# wiz16b8m4ct3_0_WIZ16B8M4CT3 register map
Vendor: Texas Instruments
Peripheral module from a debugger description file (folder J7_AHP).
Registers are 32-bit, read-write, reset 0x0 unless marked. A register's access mark holds for its fields unless they carry their own. Offsets are as the file gives them; lines under a group give offsets from that group; [hi:lo] are bit positions; {n}, {i} and the like mark numbered series; 'fields as' and 'values as' point back to an identical list; <NAME> marks a mode.

## wiz16b8m4ct3_0_WIZ16B8M4CT3 (part 1 of 12)
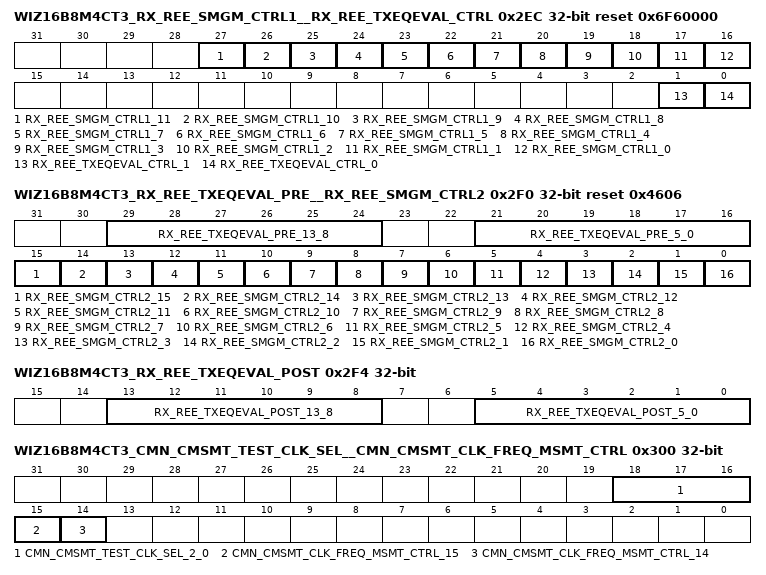
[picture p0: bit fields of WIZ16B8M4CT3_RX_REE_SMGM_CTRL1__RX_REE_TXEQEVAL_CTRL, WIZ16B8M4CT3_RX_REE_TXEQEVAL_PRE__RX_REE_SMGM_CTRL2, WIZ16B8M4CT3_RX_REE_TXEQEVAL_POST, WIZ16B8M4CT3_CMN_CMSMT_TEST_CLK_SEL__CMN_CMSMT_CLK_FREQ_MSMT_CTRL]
0x2EC WIZ16B8M4CT3_RX_REE_SMGM_CTRL1__RX_REE_TXEQEVAL_CTRL reset 0x6F60000
  [27] RX_REE_SMGM_CTRL1_11 — REE Periodic general control state machine enable standard mode 3: This bit will control if the REE periodic general control state machine will run, when xcvr_standard_mode is set to 2'b11. 1'b0 : Disabled 1'b1 : Enabled
  [26] RX_REE_SMGM_CTRL1_10 — REE Periodic general control state machine enable standard mode 2: This bit will control if the REE periodic general control state machine will run, when xcvr_standard_mode is set to 2'b10. 1'b0 : Disabled 1'b1 : Enabled
  [25] RX_REE_SMGM_CTRL1_9 — REE Periodic general control state machine enable standard mode 1: This bit will control if the REE periodic general control state machine will run, when xcvr_standard_mode is set to 2'b01. 1'b0 : Disabled 1'b1 : Enabled
  [24] RX_REE_SMGM_CTRL1_8 — REE Periodic general control state machine enable standard mode 0: This bit will control if the REE periodic general control state machine will run, when xcvr_standard_mode is set to 2'b00. 1'b0 : Disabled 1'b1 : Enabled
  [23] RX_REE_SMGM_CTRL1_7 — REE general control state machine 2 enable standard mode 3: This bit will control if the REE general control state machine 2 will run, when xcvr_standard_mode is set to 2'b11. 1'b0 : Disabled 1'b1 : Enabled
  [22] RX_REE_SMGM_CTRL1_6 — REE general control state machine 2 enable standard mode 2: This bit will control if the REE general control state machine 2 will run, when xcvr_standard_mode is set to 2'b10. 1'b0 : Disabled 1'b1 : Enabled
  [21] RX_REE_SMGM_CTRL1_5 — REE general control state machine 2 enable standard mode 1: This bit will control if the REE general control state machine 2 will run, when xcvr_standard_mode is set to 2'b01. 1'b0 : Disabled 1'b1 : Enabled
  [20] RX_REE_SMGM_CTRL1_4 — REE general control state machine 2 enable standard mode 0: This bit will control if the REE general control state machine 2 will run, when xcvr_standard_mode is set to 2'b00. 1'b0 : Disabled 1'b1 : Enabled
  [19] RX_REE_SMGM_CTRL1_3 — REE general control state machine 1 enable standard mode 3: This bit will control if the REE general control state machine 1 will run, when xcvr_standard_mode is set to 2'b11. 1'b0 : Disabled 1'b1 : Enabled
  [18] RX_REE_SMGM_CTRL1_2 — REE general control state machine 1 enable standard mode 2: This bit will control if the REE general control state machine 1 will run, when xcvr_standard_mode is set to 2'b10. 1'b0 : Disabled 1'b1 : Enabled
  [17] RX_REE_SMGM_CTRL1_1 — REE general control state machine 1 enable standard mode 1: This bit will control if the REE general control state machine 1 will run, when xcvr_standard_mode is set to 2'b01. 1'b0 : Disabled 1'b1 : Enabled
  [16] RX_REE_SMGM_CTRL1_0 — REE general control state machine 1 enable standard mode 0: This bit will control if the REE general control state machine 1 will run, when xcvr_standard_mode is set to 2'b00. 1'b0 : Disabled 1'b1 : Enabled
  [1] RX_REE_TXEQEVAL_CTRL_1 — TX equalization evaluation counter reset on gen mode change: Controls if the incremental evaluation counter will be reset to its starting value when changing gen modes. When enabled, the reset will take place on the first equalization evaluation after a gen mode change has taken place. 1'b0 : Gen mode change reset disabled. 1'b1 : Gen mode change reset enabled.
  [0] RX_REE_TXEQEVAL_CTRL_0 — TX main coefficient direction change control: This bit controls the function of the main coefficient direction change. 1'b0 : The main coefficient will always return a value of no change (2'b00), no matter what the pre and post cursor coefficient direction changes are. 1'b1 : The main coefficient will generate a return value as a function of the pre and post cursor coefficient direction change. If an increment request exists on the pre or post cursor coefficient direction change, a decrement request will be returned for the main coefficient. Similarly, if a decrement request exists on the pre or post cursor coefficient direction change, an increment request will be returned for the main coefficient.
0x2F0 WIZ16B8M4CT3_RX_REE_TXEQEVAL_PRE__RX_REE_SMGM_CTRL2 access per field reset 0x4606
  [29:24] RX_REE_TXEQEVAL_PRE_13_8 ro — TX equalization evaluator pre-emphasis increment count: Contains a count of the total number of pre-emphasis increment responses that have taken place during the TX equalization evaluator process.
  [21:16] RX_REE_TXEQEVAL_PRE_5_0 ro — TX equalization evaluator pre-emphasis decrement count: Contains a count of the total number of pre-emphasis decrement responses that have taken place during the TX equalization evaluator process.
  [15] RX_REE_SMGM_CTRL2_15 rw — REE PCIe Gen 3 TX equalization state machine E path en standard mode 3: This bit controls if the REE PCIE Gen 3 TX equalization state machine will enable the analog E path when xcvr_standard_mode is set to 2'b11. 1'b0 : Disabled 1'b1 : Enabled
  [14] RX_REE_SMGM_CTRL2_14 rw — REE PCIe Gen 3 TX equalization state machine E path en standard mode 2: This bit controls if the REE PCIE Gen 3 TX equalization state machine will enable the analog E path when xcvr_standard_mode is set to 2'b10. 1'b0 : Disabled 1'b1 : Enabled
  [13] RX_REE_SMGM_CTRL2_13 rw — REE PCIe Gen 3 TX equalization state machine E path en standard mode 1: This bit controls if the REE PCIE Gen 3 TX equalization state machine will enable the analog E path when xcvr_standard_mode is set to 2'b01. 1'b0 : Disabled 1'b1 : Enabled
  [12] RX_REE_SMGM_CTRL2_12 rw — REE PCIe Gen 3 TX equalization state machine E path en standard mode 0: This bit controls if the REE PCIE Gen 3 TX equalization state machine will enable the analog E path when xcvr_standard_mode is set to 2'b00. 1'b0 : Disabled 1'b1 : Enabled
  [11] RX_REE_SMGM_CTRL2_11 rw — REE Periodic general control state machine E path en standard mode 3: This bit controls if the REE periodic general control state machine will enable the analog E path when xcvr_standard_mode is set to 2'b11. 1'b0 : Disabled 1'b1 : Enabled
  [10] RX_REE_SMGM_CTRL2_10 rw — REE Periodic general control state machine E path en standard mode 2: This bit controls if the REE periodic general control state machine will enable the analog E path when xcvr_standard_mode is set to 2'b10. 1'b0 : Disabled 1'b1 : Enabled
  [9] RX_REE_SMGM_CTRL2_9 rw — REE Periodic general control state machine E path en standard mode 1: This bit controls if the REE periodic general control state machine will enable the analog E path when xcvr_standard_mode is set to 2'b01. 1'b0 : Disabled 1'b1 : Enabled
  [8] RX_REE_SMGM_CTRL2_8 rw — REE Periodic general control state machine E path en standard mode 0: This bit controls if the REE periodic general control state machine will enable the analog E path when xcvr_standard_mode is set to 2'b00. 1'b0 : Disabled 1'b1 : Enabled
  [7] RX_REE_SMGM_CTRL2_7 rw — REE general control state machine 2 E path en standard mode 3: This bit controls if the REE general control state machine 2 will enable the analog E path when xcvr_standard_mode is set to 2'b11. 1'b0 : Disabled 1'b1 : Enabled
  [6] RX_REE_SMGM_CTRL2_6 rw — REE general control state machine 2 E path en standard mode 2: This bit controls if the REE general control state machine 2 will enable the analog E path when xcvr_standard_mode is set to 2'b10. 1'b0 : Disabled 1'b1 : Enabled
  [5] RX_REE_SMGM_CTRL2_5 rw — REE general control state machine 2 E path en standard mode 1: This bit controls if the REE general control state machine 2 will enable the analog E path when xcvr_standard_mode is set to 2'b01. 1'b0 : Disabled 1'b1 : Enabled
  [4] RX_REE_SMGM_CTRL2_4 rw — REE general control state machine 2 E path en standard mode 0: This bit controls if the REE general control state machine 2 will enable the analog E path when xcvr_standard_mode is set to 2'b00. 1'b0 : Disabled 1'b1 : Enabled
  [3] RX_REE_SMGM_CTRL2_3 rw — REE general control state machine 1 E path en standard mode 3: This bit controls if the REE general control state machine 1 will enable the analog E path when xcvr_standard_mode is set to 2'b11. 1'b0 : Disabled 1'b1 : Enabled
  [2] RX_REE_SMGM_CTRL2_2 rw — REE general control state machine 1 E path en standard mode 2: This bit controls if the REE general control state machine 1 will enable the analog E path when xcvr_standard_mode is set to 2'b10. 1'b0 : Disabled 1'b1 : Enabled
  [1] RX_REE_SMGM_CTRL2_1 rw — REE general control state machine 1 E path en standard mode 1: This bit controls if the REE general control state machine 1 will enable the analog E path when xcvr_standard_mode is set to 2'b01. 1'b0 : Disabled 1'b1 : Enabled
  [0] RX_REE_SMGM_CTRL2_0 rw — REE general control state machine 1 E path en standard mode 0: This bit controls if the REE general control state machine 1 will enable the analog E path when xcvr_standard_mode is set to 2'b00. 1'b0 : Disabled 1'b1 : Enabled
0x2F4 WIZ16B8M4CT3_RX_REE_TXEQEVAL_POST ro
  [13:8] RX_REE_TXEQEVAL_POST_13_8 — TX equalization evaluator post-emphasis increment count: Contains a count of the total number of post-emphasis increment responses that have taken place during the TX equalization evaluator process.
  [5:0] RX_REE_TXEQEVAL_POST_5_0 — TX equalization evaluator post-emphasis decrement count: Contains a count of the total number of post-emphasis decrement responses that have taken place during the TX equalization evaluator process.
0x300 WIZ16B8M4CT3_CMN_CMSMT_TEST_CLK_SEL__CMN_CMSMT_CLK_FREQ_MSMT_CTRL access per field
  [18:16] CMN_CMSMT_TEST_CLK_SEL_2_0 rw — Test clock select: This field drives the test_clk_select pin, in order to control an external MUX for selecting between multiple test clocks to measure. The following is the encoding for this field, and the clock each value selects. 3'b000 : PLL 0 reference clock 3'b001 : PLL 0 feedback divider clock 3'b010 : PLL 0 full rate clock 3'b011 : PLL 1 reference clock 3'b100 : PLL 1 feedback divider clock 3'b101 : PLL 1 full rate clock 3'b110 : Process monitor clock 3'b111 : Signal detect clock
  [15] CMN_CMSMT_CLK_FREQ_MSMT_CTRL_15 rw — Run test clock measurement: Activating (1'b1) this bit will run the test clock measurement process. This bit must remain active until the test clock measurement process is complete, as indicated by the test clock measurement done bit in this register. To start another measurement process, this bit must first be driven inactive then driven active again. Note: Both of the clocks used to generate the ref_clk and test_clk clocks must be active prior to setting or clearing this bit. Note: The values in the Test clock selection register and Reference clock timer value register must be set prior to activating this bit.
  [14] CMN_CMSMT_CLK_FREQ_MSMT_CTRL_14 ro — Test clock measurement done: This bit will be set to 1'b1 when the test clock measurement process is complete. It will be cleared by the deactivation of the start test clock measurement bit in this register.
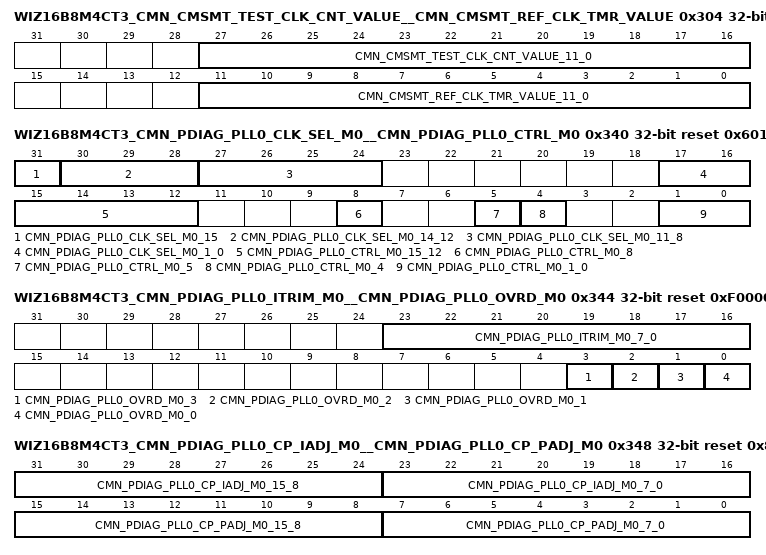
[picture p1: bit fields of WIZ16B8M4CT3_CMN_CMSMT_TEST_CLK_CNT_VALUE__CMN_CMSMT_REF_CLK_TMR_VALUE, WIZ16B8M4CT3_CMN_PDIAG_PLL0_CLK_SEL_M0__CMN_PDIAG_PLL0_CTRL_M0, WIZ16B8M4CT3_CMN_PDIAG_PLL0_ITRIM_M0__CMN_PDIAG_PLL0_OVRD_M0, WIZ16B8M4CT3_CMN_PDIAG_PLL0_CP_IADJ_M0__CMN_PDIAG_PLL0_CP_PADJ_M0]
0x304 WIZ16B8M4CT3_CMN_CMSMT_TEST_CLK_CNT_VALUE__CMN_CMSMT_REF_CLK_TMR_VALUE access per field
  [27:16] CMN_CMSMT_TEST_CLK_CNT_VALUE_11_0 ro — Test clock counter value: When the test clock measurement process is complete, the value in this field specifies the number of test clock cycles that were counted in the time specified by the reference clock timer value. This field is only valid while the test clock measurement done bit in the Clock frequency measurement control register is active.
  [11:0] CMN_CMSMT_REF_CLK_TMR_VALUE_11_0 rw — Reference clock timer value : This specifies the amount of time, in reference clock cycles, to count test clock cycles. This value minus 1 is loaded into the reference clock timer. A value of 0 for this field is not valid when running this function.
0x340 WIZ16B8M4CT3_CMN_PDIAG_PLL0_CLK_SEL_M0__CMN_PDIAG_PLL0_CTRL_M0 reset 0x6011012
  [31] CMN_PDIAG_PLL0_CLK_SEL_M0_15 — PLL 0 clock 1 divider enable: This bit enables the divider used to generate the cmnda_pll0_clk_1, from the PLL high speed clock.
  [30:28] CMN_PDIAG_PLL0_CLK_SEL_M0_14_12 — PLL 0 clock 1 divider select: This field selects the divider value used to generate the cmnda_pll0_clk_1, from the PLL high speed clock, by driving the cmnda_pll0_clk_1_div_sel signal to the analog. The encoding of this signal is as follows. All codes currently result in divide by 16.
  [27:24] CMN_PDIAG_PLL0_CLK_SEL_M0_11_8 — PLL 0 clock 0 and derived reference clock divider select: This field selects the divider value used to generate the cmnda_pll0_clk_0 and derived reference clock, from the PLL high speed clock, by driving the cmnda_pll0_clk_0_div_sel signal to the analog. The encoding of this signal is as follows. Note: There are different divider values per bit for associated with each clock.
  [17:16] CMN_PDIAG_PLL0_CLK_SEL_M0_1_0 — PLL 0 clock select: This field selects one of 3 possible high speed output clocks from PLL 0, to drive on the high speed analog clock 0, by driving the cmnda_pll0_clk_sel signal to the analog. The encoding for this is as follows. 2'b00: Divide by 1 2'b01: Divide by 2 2'b10: Divide by 4 2'b11: Reserved
  [15:12] CMN_PDIAG_PLL0_CTRL_M0_15_12 — This field controls the Ring VCO Frequency drift with temperature. It controls the mix of vtref bias and external bias to keep the temperature drift for the ring low, by driving the cmnda_pll0_vco_ring_cmos_sel signal going into the common analog.
  [8] CMN_PDIAG_PLL0_CTRL_M0_8 — PLL VCO select: Selects the VCO mode of operation, by driving the cmnda_pll0_vco_sel signal going into the common analog. 1'b0: LC tank mode 1'b1: Ring oscillator mode
  [5] CMN_PDIAG_PLL0_CTRL_M0_5 — PLL feedback divider clock select: This signal selects which internal PLL clock will be used to drive the cmnda_pll0_fb_divider_clk, by driving the cmnda_pll0_fb_divider_clk_sel signal going into the common analog. 1'b0: Feedback divider clock 1'b1: PLL digital rate clock
  [4] CMN_PDIAG_PLL0_CTRL_M0_4 — PLL feedback divider pre-scale: controls the feedback divider pre-scale, by driving the cmnda_pll0_div24_sel signal going into the common analog. One should read the description of the PLL in section 10.4 Dual VCO PLL on page 411 for detailed information about the function of this divider control. 1'b0: Divide by 2 - When using the delta sigma modulator, this setting results in lower noise on the PLL output clock, but higher power. 1'b1: Divide by 4 - When using the delta sigma modulator, this setting results in higher noise on the PLL output clock, but lower power. This setting is ideal for cases when the delta sigma modulator is not used, because is results in both lower noise and lower power.
  [1:0] CMN_PDIAG_PLL0_CTRL_M0_1_0 — PLL PFD reset delay: Controls the minimum reset pulse width for the PFD. This drives the cmnda_pll0_pfd_rst_dly signal going into the common analog. The following lists the reset pulse width values for typical conditions for each of the possible values for this field. 2'b00 : Delay = 257.5 pSec (minimum) 2'b01 : Delay = 337.4 pSec 2'b10 : Delay = 415.2 pSec 2'b11 : Delay = 493.2 pSec (maximum)
0x344 WIZ16B8M4CT3_CMN_PDIAG_PLL0_ITRIM_M0__CMN_PDIAG_PLL0_OVRD_M0 access per field reset 0xF0000
  [23:16] CMN_PDIAG_PLL0_ITRIM_M0_7_0 rw — PLL VCO bias current trim code: Controls the tank currents in the PLL LC tank circuit. This field drives the cmnda_pll0_vco_bias_current_trim signal going to the analog.
  [3] CMN_PDIAG_PLL0_OVRD_M0_3 rw — PLL VCO calibration enable override enable: When active (1'b1), the PLL VCO calibration enable override bit in this register, can be used to directly control the enable of the VCO calibration function in the PLL (instead of the VCO calibration module).
  [2] CMN_PDIAG_PLL0_OVRD_M0_2 rw — PLL VCO calibration enable override: When enabled by the PLL VCO calibration enable override enable bit in this register, this bit will directly control the enable of the VCO calibration function in the PLL.
  [1] CMN_PDIAG_PLL0_OVRD_M0_1 rw — PLL phase lock detect enable : Enables the diagnostic PLL phase lock detect function in the analog. This activates the cmnda_pll0_ph_lock_en signal going into the analog.
  [0] CMN_PDIAG_PLL0_OVRD_M0_0 ro — PLL phase lock detected : When enabled by the PLL phase lock detect enable bit in this register, this bit indicates that a PLL phase lock has been detected. This is the current value of the cmnda_pll0_ph_lock_detect signal coming from the analog.
0x348 WIZ16B8M4CT3_CMN_PDIAG_PLL0_CP_IADJ_M0__CMN_PDIAG_PLL0_CP_PADJ_M0 reset 0x8080028
  [31:24] CMN_PDIAG_PLL0_CP_IADJ_M0_15_8 — PLL charge pump integral path capacitance adjust: Adjusts the charge pump integral path capacitance, by driving the cmnda_pll0_cp_int_cap_adj signal going to the analog.
  [23:16] CMN_PDIAG_PLL0_CP_IADJ_M0_7_0 — PLL charge pump integral path current adjust: Adjusts the charge pump integral path current, by driving the cmnda_pll0_cp_int_cur_adj signal going to the analog.
  [15:8] CMN_PDIAG_PLL0_CP_PADJ_M0_15_8 — PLL charge pump proportional path capacitance adjust: Adjusts the charge pump proportional path capacitance, by driving the cmnda_pll0_cp_prop_cap_adj signal going to the analog.
  [7:0] CMN_PDIAG_PLL0_CP_PADJ_M0_7_0 — PLL charge pump proportional path current adjust: Adjusts the charge pump proportional path current, by driving the cmnda_pll0_cp_prop_cur_adj signal going to the analog.
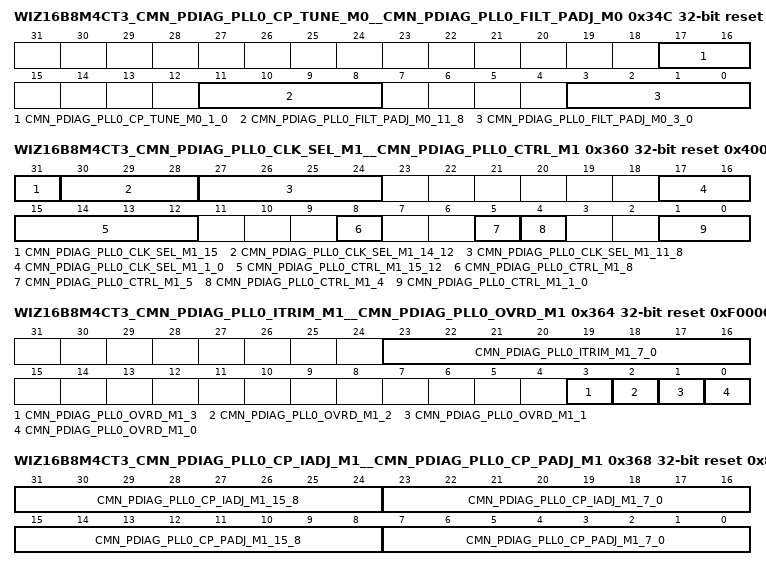
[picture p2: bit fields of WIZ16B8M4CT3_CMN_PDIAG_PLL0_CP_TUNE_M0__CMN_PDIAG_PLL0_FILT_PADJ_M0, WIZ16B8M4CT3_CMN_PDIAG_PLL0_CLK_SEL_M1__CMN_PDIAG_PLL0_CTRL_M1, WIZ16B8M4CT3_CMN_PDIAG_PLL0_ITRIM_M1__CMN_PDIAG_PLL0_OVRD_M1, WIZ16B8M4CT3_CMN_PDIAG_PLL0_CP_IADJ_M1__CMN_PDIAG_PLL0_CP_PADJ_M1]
0x34C WIZ16B8M4CT3_CMN_PDIAG_PLL0_CP_TUNE_M0__CMN_PDIAG_PLL0_FILT_PADJ_M0 reset 0x10000
  [17:16] CMN_PDIAG_PLL0_CP_TUNE_M0_1_0 — PLL charge pump calibration reference voltage tune: Adjusts the charge pump calibration reference voltage, by driving the cmnda_pll0_cp_vref_tune signal going to the analog. 2'b00 : minimum 2'b01 2'b10 2'b11 maximum
  [11:8] CMN_PDIAG_PLL0_FILT_PADJ_M0_11_8 — PLL proportional path filter capacitance adjust: Adjusts the proportional path filter capacitance, by driving the cmnda_pll0_filt_c_adj signal going to the analog.
  [3:0] CMN_PDIAG_PLL0_FILT_PADJ_M0_3_0 — PLL proportional path filter resistance adjust: Adjusts the proportional path filter resistance, by driving the cmnda_pll0_filt_r_adj signal going to the analog.
0x360 WIZ16B8M4CT3_CMN_PDIAG_PLL0_CLK_SEL_M1__CMN_PDIAG_PLL0_CTRL_M1 reset 0x4001012
  [31] CMN_PDIAG_PLL0_CLK_SEL_M1_15 — PLL 0 clock 1 divider enable: This bit enables the divider used to generate the cmnda_pll0_clk_1, from the PLL high speed clock.
  [30:28] CMN_PDIAG_PLL0_CLK_SEL_M1_14_12 — PLL 0 clock 1 divider select: This field selects the divider value used to generate the cmnda_pll0_clk_1, from the PLL high speed clock, by driving the cmnda_pll0_clk_1_div_sel signal to the analog. The encoding of this signal is as follows. All codes currently result in divide by 16.
  [27:24] CMN_PDIAG_PLL0_CLK_SEL_M1_11_8 — PLL 0 clock 0 and derived reference clock divider select: This field selects the divider value used to generate the cmnda_pll0_clk_0 and derived reference clock, from the PLL high speed clock, by driving the cmnda_pll0_clk_0_div_sel signal to the analog. The encoding of this signal is as follows. Note: There are different divider values per bit for associated with each clock.
  [17:16] CMN_PDIAG_PLL0_CLK_SEL_M1_1_0 — PLL 0 clock select: This field selects one of 3 possible high speed output clocks from PLL 0, to drive on the high speed analog clock 0, by driving the cmnda_pll0_clk_sel signal to the analog. The encoding for this is as follows. 2'b00: Divide by 1 2'b01: Divide by 2 2'b10: Divide by 4 2'b11: Reserved
  [15:12] CMN_PDIAG_PLL0_CTRL_M1_15_12 — This field controls the Ring VCO Frequency drift with temperature. It controls the mix of vtref bias and external bias to keep the temperature drift for the ring low, by driving the cmnda_pll0_vco_ring_cmos_sel signal going into the common analog.
  [8] CMN_PDIAG_PLL0_CTRL_M1_8 — PLL VCO select: Selects the VCO mode of operation, by driving the cmnda_pll0_vco_sel signal going into the common analog. 1'b0: LC tank mode 1'b1: Ring oscillator mode
  [5] CMN_PDIAG_PLL0_CTRL_M1_5 — PLL feedback divider clock select: This signal selects which internal PLL clock will be used to drive the cmnda_pll0_fb_divider_clk,driving the cmnda_pll0_fb_divider_clk_sel signal going into the common analog. 1'b0: Feedback divider clock 1'b1: PLL digital rate clock
  [4] CMN_PDIAG_PLL0_CTRL_M1_4 — PLL feedback divider pre-scale: controls the feedback divider pre-scale, by driving the cmnda_pll0_div24_sel signal going into the common analog. One should read the description of the PLL in section 10.4 Dual VCO PLL on page 411 for detailed information about the function of this divider control. 1'b0: Divide by 2 - When using the delta sigma modulator, this setting results in lower noise on the PLL output clock, but higher power. 1'b1: Divide by 4 - When using the delta sigma modulator, this setting results in higher noise on the PLL output clock, but lower power. This setting is ideal for cases when the delta sigma modulator is not used, because is results in both lower noise and lower power.
  [1:0] CMN_PDIAG_PLL0_CTRL_M1_1_0 — PLL PFD reset delay: Controls the minimum reset pulse width for the PFD. This drives the cmnda_pll0_pfd_rst_dly signal going into the common analog. The following lists the reset pulse width values for typical conditions for each of the possible values for this field. 2'b00 : Delay = 257.5 pSec (minimum) 2'b01 : Delay = 337.4 pSec 2'b10 : Delay = 415.2 pSec 2'b11 : Delay = 493.2 pSec (maximum)
0x364 WIZ16B8M4CT3_CMN_PDIAG_PLL0_ITRIM_M1__CMN_PDIAG_PLL0_OVRD_M1 access per field reset 0xF0000
  [23:16] CMN_PDIAG_PLL0_ITRIM_M1_7_0 rw — PLL VCO bias current trim code: Controls the tank currents in the PLL LC tank circuit. This field drives the cmnda_pll0_vco_bias_current_trim signal going to the analog.
  [3] CMN_PDIAG_PLL0_OVRD_M1_3 rw — PLL VCO calibration enable override enable: When active (1'b1), the PLL VCO calibration enable override bit in this register, can be used to directly control the enable of the VCO calibration function in the PLL (instead of the VCO calibration module).
  [2] CMN_PDIAG_PLL0_OVRD_M1_2 rw — PLL VCO calibration enable override: When enabled by the PLL VCO calibration enable override enable bit in this register, this bit will directly control the enable of the VCO calibration function in the PLL.
  [1] CMN_PDIAG_PLL0_OVRD_M1_1 rw — PLL phase lock detect enable : Enables the diagnostic PLL phase lock detect function in the analog. This activates the cmnda_pll0_ph_lock_en signal going into the analog.
  [0] CMN_PDIAG_PLL0_OVRD_M1_0 ro — PLL phase lock detected : When enabled by the PLL phase lock detect enable bit in this register, this bit indicates that a PLL phase lock has been detected. This is the current value of the cmnda_pll0_ph_lock_detect signal coming from the analog.
0x368 WIZ16B8M4CT3_CMN_PDIAG_PLL0_CP_IADJ_M1__CMN_PDIAG_PLL0_CP_PADJ_M1 reset 0x8080128
  [31:24] CMN_PDIAG_PLL0_CP_IADJ_M1_15_8 — PLL charge pump integral path capacitance adjust: Adjusts the charge pump integral path capacitance, by driving the cmnda_pll0_cp_int_cap_adj signal going to the analog.
  [23:16] CMN_PDIAG_PLL0_CP_IADJ_M1_7_0 — PLL charge pump integral path current adjust: Adjusts the charge pump integral path current, by driving the cmnda_pll0_cp_int_cur_adj signal going to the analog.
  [15:8] CMN_PDIAG_PLL0_CP_PADJ_M1_15_8 — PLL charge pump proportional path capacitance adjust: Adjusts the charge pump proportional path capacitance, by driving the cmnda_pll0_cp_prop_cap_adj signal going to the analog.
  [7:0] CMN_PDIAG_PLL0_CP_PADJ_M1_7_0 — PLL charge pump proportional path current adjust: Adjusts the charge pump proportional path current, by driving the cmnda_pll0_cp_prop_cur_adj signal going to the analog.
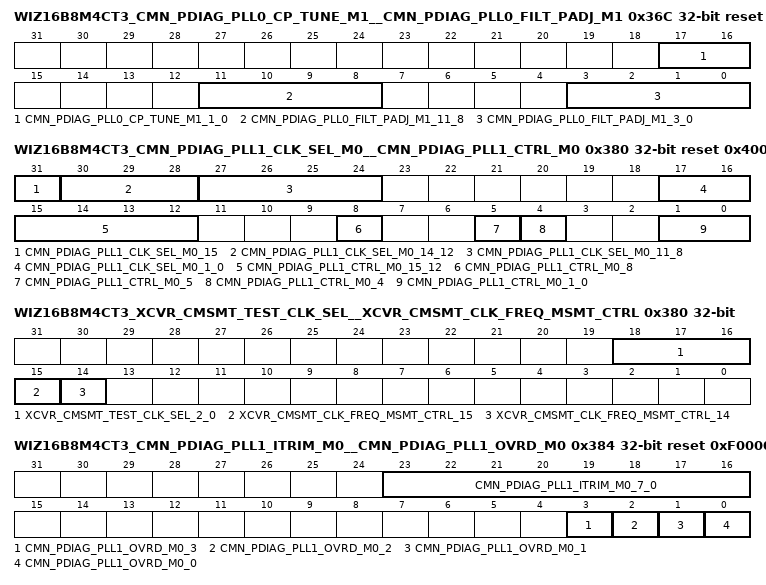
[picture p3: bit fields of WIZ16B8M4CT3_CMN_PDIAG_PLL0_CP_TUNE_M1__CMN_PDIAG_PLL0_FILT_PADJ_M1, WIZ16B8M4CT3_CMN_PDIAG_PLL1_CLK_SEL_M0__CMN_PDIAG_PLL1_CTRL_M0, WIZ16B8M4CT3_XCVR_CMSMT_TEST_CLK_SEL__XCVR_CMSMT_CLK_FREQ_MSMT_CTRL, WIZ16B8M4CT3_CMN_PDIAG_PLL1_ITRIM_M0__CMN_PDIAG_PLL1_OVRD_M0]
0x36C WIZ16B8M4CT3_CMN_PDIAG_PLL0_CP_TUNE_M1__CMN_PDIAG_PLL0_FILT_PADJ_M1 reset 0x10000
  [17:16] CMN_PDIAG_PLL0_CP_TUNE_M1_1_0 — PLL charge pump calibration reference voltage tune: Adjusts the charge pump calibration reference voltage, by driving the cmnda_pll0_cp_vref_tune signal going to the analog. 2'b00 : minimum 2'b01 2'b10 2'b11 maximum
  [11:8] CMN_PDIAG_PLL0_FILT_PADJ_M1_11_8 — PLL proportional path filter capacitance adjust: Adjusts the proportional path filter capacitance, by driving the cmnda_pll0_filt_c_adj signal going to the analog.
  [3:0] CMN_PDIAG_PLL0_FILT_PADJ_M1_3_0 — PLL proportional path filter resistance adjust: Adjusts the proportional path filter resistance, by driving the cmnda_pll0_filt_r_adj signal going to the analog.
0x380 WIZ16B8M4CT3_CMN_PDIAG_PLL1_CLK_SEL_M0__CMN_PDIAG_PLL1_CTRL_M0 reset 0x4001012
  [31] CMN_PDIAG_PLL1_CLK_SEL_M0_15 — PLL 1 clock 1 divider enable: This bit enables the divider used to generate the cmnda_pll1_clk_1, from the PLL high speed clock.
  [30:28] CMN_PDIAG_PLL1_CLK_SEL_M0_14_12 — PLL 1 clock 1 divider select: This field selects the divider value used to generate the cmnda_pll1_clk_1, from the PLL high speed clock, by driving the cmnda_pll1_clk_1_div_sel signal to the analog. The encoding of this signal is as follows. All codes currently result in divide by 16.
  [27:24] CMN_PDIAG_PLL1_CLK_SEL_M0_11_8 — PLL 1 clock 0 and derived reference clock divider select: This field selects the divider value used to generate the cmnda_pll1_clk_0 and derived reference clock, from the PLL high speed clock, by driving the cmnda_pll1_clk_0_div_sel signal to the analog. The encoding of this signal is as follows. Note: There are different divider values per bit for associated with each clock.
  [17:16] CMN_PDIAG_PLL1_CLK_SEL_M0_1_0 — PLL 1 clock select: This field selects one of 3 possible high speed output clocks from PLL 1, to drive on the high speed analog clock 1, by driving the cmnda_pll1_clk_sel signal to the analog. The encoding for this is as follows. 2'b00: Divide by 1 2'b01: Divide by 2 2'b10: Divide by 4 2'b11: Reserved
  [15:12] CMN_PDIAG_PLL1_CTRL_M0_15_12 — This field controls the Ring VCO Frequency drift with temperature. It controls the mix of vtref bias and external bias to keep the temperature drift for the ring low, by driving the cmnda_pll1_vco_ring_cmos_sel signal going into the common analog.
  [8] CMN_PDIAG_PLL1_CTRL_M0_8 — PLL VCO select: Selects the VCO mode of operation, by driving the cmnda_pll1_vco_sel signal going into the common analog. 1'b0: LC tank mode 1'b1: Ring oscillator mode
  [5] CMN_PDIAG_PLL1_CTRL_M0_5 — PLL feedback divider clock select: This signal selects which internal PLL clock will be used to drive the cmnda_pll1_fb_divider_clk,driving the cmnda_pll1_fb_divider_clk_sel signal going into the common analog. 1'b0: Feedback divider clock 1'b1: PLL digital rate clock
  [4] CMN_PDIAG_PLL1_CTRL_M0_4 — PLL feedback divider pre-scale: controls the feedback divider pre-scale, by driving the cmnda_pll1_div24_sel signal going into the common analog. One should read the description of the PLL in section 10.4 Dual VCO PLL on page 411 for detailed information about the function of this divider control. 1'b0: Divide by 2 - When using the delta sigma modulator, this setting results in lower noise on the PLL output clock, but higher power. 1'b1: Divide by 4 - When using the delta sigma modulator, this setting results in higher noise on the PLL output clock, but lower power. This setting is ideal for cases when the delta sigma modulator is not used, because is results in both lower noise and lower power.
  [1:0] CMN_PDIAG_PLL1_CTRL_M0_1_0 — PLL PFD reset delay: Controls the minimum reset pulse width for the PFD. This drives the cmnda_pll1_pfd_rst_dly signal going into the common analog. The following lists the reset pulse width values for typical conditions for each of the possible values for this field. 2'b00 : Delay = 257.5 pSec (minimum) 2'b01 : Delay = 337.4 pSec 2'b10 : Delay = 415.2 pSec 2'b11 : Delay = 493.2 pSec (maximum)
0x380 WIZ16B8M4CT3_XCVR_CMSMT_TEST_CLK_SEL__XCVR_CMSMT_CLK_FREQ_MSMT_CTRL access per field
  [18:16] XCVR_CMSMT_TEST_CLK_SEL_2_0 rw — Test clock select: This field drives the test_clk_select pin, in order to control an external MUX for selecting between multiple test clocks to measure. The following is the encoding for this field, and the clock each value selects. 3'b000 : Transmitter data clock 3'b001 : Serializer clock 3'b010 : Receiver data clock 3'b011 : Deserializer clock 3'b100 : Receiver 2X data clock 3'b101 : Deserializer 2X clock 3'b110 : Signal detect clock 3'b111 : Reserved
  [15] XCVR_CMSMT_CLK_FREQ_MSMT_CTRL_15 rw — Run test clock measurement: Activating (1'b1) this bit will run the test clock measurement process. This bit must remain active until the test clock measurement process is complete, as indicated by the test clock measurement done bit in this register. To start another measurement process, this bit must first be driven inactive then driven active again. Note: Both of the clocks used to generate the ref_clk and test_clk clocks must be active prior to setting or clearing this bit. Note: The values in the Test clock selection register and Reference clock timer value register must be set prior to activating this bit.
  [14] XCVR_CMSMT_CLK_FREQ_MSMT_CTRL_14 ro — Test clock measurement done: This bit will be set to 1'b1 when the test clock measurement process is complete. It will be cleared by the deactivation of the start test clock measurement bit in this register.
0x384 WIZ16B8M4CT3_CMN_PDIAG_PLL1_ITRIM_M0__CMN_PDIAG_PLL1_OVRD_M0 access per field reset 0xF0000
  [23:16] CMN_PDIAG_PLL1_ITRIM_M0_7_0 rw — PLL VCO bias current trim code: Controls the tank currents in the PLL LC tank circuit. This field drives the cmnda_pll1_vco_bias_current_trim signal going to the analog.
  [3] CMN_PDIAG_PLL1_OVRD_M0_3 rw — PLL VCO calibration enable override enable: When active (1'b1), the PLL VCO calibration enable override bit in this register, can be used to directly control the enable of the VCO calibration function in the PLL (instead of the VCO calibration module).
  [2] CMN_PDIAG_PLL1_OVRD_M0_2 rw — PLL VCO calibration enable override: When enabled by the PLL VCO calibration enable override enable bit in this register, this bit will directly control the enable of the VCO calibration function in the PLL.
  [1] CMN_PDIAG_PLL1_OVRD_M0_1 rw — PLL phase lock detect enable : Enables the diagnostic PLL phase lock detect function in the analog. This activates the cmnda_pll1_ph_lock_en signal going into the analog.
  [0] CMN_PDIAG_PLL1_OVRD_M0_0 ro — PLL phase lock detected : When enabled by the PLL phase lock detect enable bit in this register, this bit indicates that a PLL phase lock has been detected. This is the current value of the cmnda_pll1_ph_lock_detect signal coming from the analog.
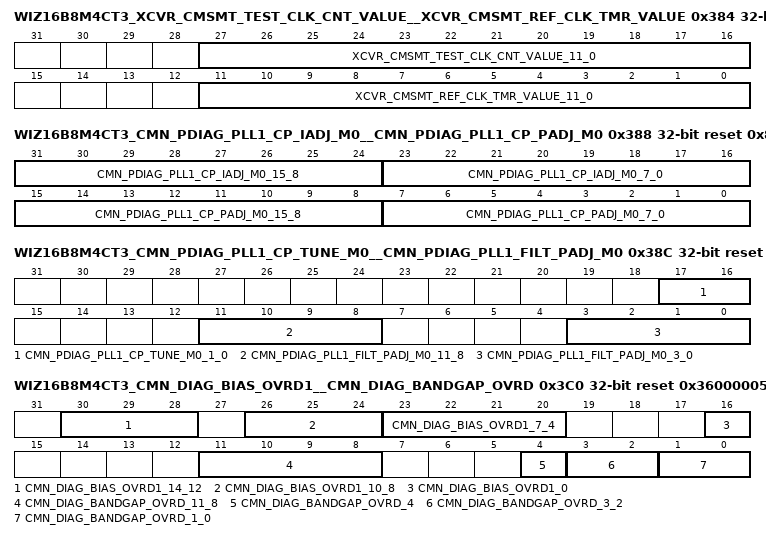
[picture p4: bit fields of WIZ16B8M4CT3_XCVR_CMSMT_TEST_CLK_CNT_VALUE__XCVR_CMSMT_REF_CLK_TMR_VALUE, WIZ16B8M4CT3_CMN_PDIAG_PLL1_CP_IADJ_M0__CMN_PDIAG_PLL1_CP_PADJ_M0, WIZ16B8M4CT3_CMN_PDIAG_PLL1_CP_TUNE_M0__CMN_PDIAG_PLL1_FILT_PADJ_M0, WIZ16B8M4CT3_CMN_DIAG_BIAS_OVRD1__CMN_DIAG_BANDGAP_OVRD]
0x384 WIZ16B8M4CT3_XCVR_CMSMT_TEST_CLK_CNT_VALUE__XCVR_CMSMT_REF_CLK_TMR_VALUE access per field
  [27:16] XCVR_CMSMT_TEST_CLK_CNT_VALUE_11_0 ro — Test clock counter value: When the test clock measurement process is complete, the value in this field specifies the number of test clock cycles that were counted in the time specified by the reference clock timer value. This field is only valid while the test clock measurement done bit in the Clock frequency measurement control register is active.
  [11:0] XCVR_CMSMT_REF_CLK_TMR_VALUE_11_0 rw — Reference clock timer value : This specifies the amount of time, in reference clock cycles, to count test clock cycles. This value minus 1 is loaded into the reference clock timer. A value of 0 for this field is not valid when running this function.
0x388 WIZ16B8M4CT3_CMN_PDIAG_PLL1_CP_IADJ_M0__CMN_PDIAG_PLL1_CP_PADJ_M0 reset 0x8080128
  [31:24] CMN_PDIAG_PLL1_CP_IADJ_M0_15_8 — PLL charge pump integral path capacitance adjust: Adjusts the charge pump integral path capacitance, by driving the cmnda_pll1_cp_int_cap_adj signal going to the analog.
  [23:16] CMN_PDIAG_PLL1_CP_IADJ_M0_7_0 — PLL charge pump integral path current adjust: Adjusts the charge pump integral path current, by driving the cmnda_pll1_cp_int_cur_adj signal going to the analog.
  [15:8] CMN_PDIAG_PLL1_CP_PADJ_M0_15_8 — PLL charge pump proportional path capacitance adjust: Adjusts the charge pump proportional path capacitance, by driving the cmnda_pll1_cp_prop_cap_adj signal going to the analog.
  [7:0] CMN_PDIAG_PLL1_CP_PADJ_M0_7_0 — PLL charge pump proportional path current adjust: Adjusts the charge pump proportional path current, by driving the cmnda_pll0_cp_prop_cur_adj signal going to the analog.
0x38C WIZ16B8M4CT3_CMN_PDIAG_PLL1_CP_TUNE_M0__CMN_PDIAG_PLL1_FILT_PADJ_M0 reset 0x10000
  [17:16] CMN_PDIAG_PLL1_CP_TUNE_M0_1_0 — PLL charge pump calibration reference voltage tune: Adjusts the charge pump calibration reference voltage, by driving the cmnda_pll1_cp_vref_tune signal going to the analog. 2'b00 : minimum 2'b01 2'b10 2'b11 maximum
  [11:8] CMN_PDIAG_PLL1_FILT_PADJ_M0_11_8 — PLL proportional path filter capacitance adjust: Adjusts the proportional path filter capacitance, by driving the cmnda_pll1_filt_c_adj signal going to the analog.
  [3:0] CMN_PDIAG_PLL1_FILT_PADJ_M0_3_0 — PLL proportional path filter resistance adjust: Adjusts the proportional path filter resistance, by driving the cmnda_pll1_filt_r_adj signal going to the analog.
0x3C0 WIZ16B8M4CT3_CMN_DIAG_BIAS_OVRD1__CMN_DIAG_BANDGAP_OVRD access per field reset 0x36000005
  [30:28] CMN_DIAG_BIAS_OVRD1_14_12 rw — Receiver resistor calibration current adjust: This field is used to adjust the receiver resistor calibration bias current. It drives the cmnda_bias_rx_rescal_adj signal going to the analog. The following list shows the encoding of this field. 3'b000 : 110.72 uA 3'b001 : 112.50 uA 3'b010 : 114.29 uA 3'b011 : 116.07 uA 3'b100 : 117.86 uA 3'b101 : 119.64 uA 3'b110 : 121.43 uA 3'b111 : 123.22 uA
  [26:24] CMN_DIAG_BIAS_OVRD1_10_8 rw — Transmitter resistor calibration current adjust: This field is used to adjust the transmitter resistor calibration bias current. It drives the cmnda_bias_tx_rescal_adj signal going to the analog. The following list shows the encoding of this field. 3'b000 : 110.72 uA 3'b001 : 112.50 uA 3'b010 : 114.29 uA 3'b011 : 116.07 uA 3'b100 : 117.86 uA 3'b101 : 119.64 uA 3'b110 : 121.43 uA 3'b111 : 123.22 uA
  [23:20] CMN_DIAG_BIAS_OVRD1_7_4 rw — Reserved - spare
  [16] CMN_DIAG_BIAS_OVRD1_0 rw — Reserved - spare
  [11:8] CMN_DIAG_BANDGAP_OVRD_11_8 ro — Bandgap startup circuit startup count : Identifies the status of the bandgap startup counter. This bit is driven by the cmnda_bias_bg_start_count signal coming from the analog.
  [4] CMN_DIAG_BANDGAP_OVRD_4 rw — Bandgap startup circuit select : Selects the startup circuit to be used for the bias / bandgap circuits, by driving the cmnda_bias_bg_start_sel signal going to the analog. 1'b0: Analog comparator startup circuit 1'b1: Ring oscillator startup circuit
  [3:2] CMN_DIAG_BANDGAP_OVRD_3_2 rw — Bandgap startup circuit sense voltage adjust : This field is used to adjust the bandgap startup circuit sense voltage, by driving the cmnda_bias_bg_start_adj signal to the analog. The following list shows the encoding of this field. 2'b00 : 543.0 mV 2'b01 : 558.5 mV 2'b10 : 574.0 mV 2'b11 : Reserved
  [1:0] CMN_DIAG_BANDGAP_OVRD_1_0 rw — Bandgap voltage adjust : This field is used to adjust the bandgap voltage, by driving the cmnda_bias_bg_adj signal to the analog. The following list shows the encoding of this field. 2'b00 : 414.7 mV 2'b01 : 440.7 mV 2'b10 : 446.7 mV 2'b11 : 446.7 mV
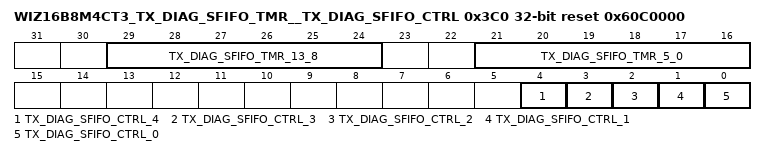
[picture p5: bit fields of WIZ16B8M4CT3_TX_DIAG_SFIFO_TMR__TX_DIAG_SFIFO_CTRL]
0x3C0 WIZ16B8M4CT3_TX_DIAG_SFIFO_TMR__TX_DIAG_SFIFO_CTRL access per field reset 0x60C0000
  [29:24] TX_DIAG_SFIFO_TMR_13_8 rw — FIFO alignment settle delay: This field specifies the number of clocks to wait for a prior change to the enqueue pointer to complete before initiating the check phase of the alignment procedure in the sync FIFO. It drives the fifo_align_settle_del pin of the FIFO.
  [21:16] TX_DIAG_SFIFO_TMR_5_0 rw — FIFO alignment detect delay: This field specifies the number of clocks to wait in the delay state for each phase of the alignment procedure in the sync FIFO. It drives the fifo_align_detect_del pin of the FIFO.
  [4] TX_DIAG_SFIFO_CTRL_4 rw — FIFO enqueue pointer bump: This bit can be used to decrement the enqueue pointer relative to the dequeue pointer, for diagnostic purposes. Changing this bit from a value of 1'b0 to 1'b1 will trigger a single decrement of the enqueue pointer.
  [3] TX_DIAG_SFIFO_CTRL_3 ro — FIFO pointers overlapping: This bit indicates that the current enqueue and dequeue pointers have been detected as overlapping. This is not necessarily an error condition. For example, the pointers could be overlapping but the enqueue pointer could be skewed later in time relative to the dequeue pointer. In this scenario, the actual enqueue would take place after the dequeue. The intention of this bit is to be used with the FIFO enqueue pointer bump bit in this register to move the pointers around and determine their relative positions. Note: The reset value for this field is with the transceiver data path power island switched off. In cases where this power island is switched on, the reset value be 1'b1
  [2] TX_DIAG_SFIFO_CTRL_2 ro — FIFO alignment acknowledge: This bit indicates that the FIFO alignment process is complete, as initiated either automatically by the hardware of the FIFO alignment enable override bits in this register. This bit is driven directly by the fifo_align_ack pin of the FIFO.
  [1] TX_DIAG_SFIFO_CTRL_1 rw — FIFO alignment enable override enable: This bit enables the FIFO alignment enable override register to drive the fifo_align_en pin of the FIFO directly for diagnostic purposes. 1'b0: Override disabled 1'b1: Override enabled.
  [0] TX_DIAG_SFIFO_CTRL_0 rw — FIFO alignment enable override: When enabled by the FIFO alignment enable override enable bit in this register, this bit directly controls the fifo_align_en pin of the FIFO to provide a means of running the FIFO alignment function for diagnostic purposes.
